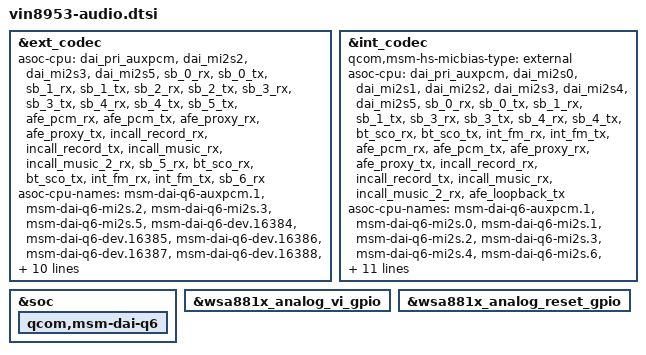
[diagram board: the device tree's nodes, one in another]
&ext_codec {
	/* WARNING: Override
	   Changes:
	   - Remove "proxy_rx", "proxy_tx"
	*/
	asoc-cpu = <&dai_pri_auxpcm>,
		<&dai_mi2s2>, <&dai_mi2s3>, <&dai_mi2s5>,
		<&sb_0_rx>, <&sb_0_tx>, <&sb_1_rx>, <&sb_1_tx>,
		<&sb_2_rx>, <&sb_2_tx>, <&sb_3_rx>, <&sb_3_tx>,
		<&sb_4_rx>, <&sb_4_tx>, <&sb_5_tx>,
		<&afe_pcm_rx>, <&afe_pcm_tx>,
		<&afe_proxy_rx>, <&afe_proxy_tx>,
		<&incall_record_rx>, <&incall_record_tx>,
		<&incall_music_rx>, <&incall_music_2_rx>,
		<&sb_5_rx>, <&bt_sco_rx>, <&bt_sco_tx>,
		<&int_fm_rx>, <&int_fm_tx>, <&sb_6_rx>;

	/* WARNING: Override
	   Changes:
	   - Remove "msm-dai-q6-dev.8194", "msm-dai-q6-dev.8195"
	*/
	asoc-cpu-names = "msm-dai-q6-auxpcm.1",
		"msm-dai-q6-mi2s.2", "msm-dai-q6-mi2s.3",
		"msm-dai-q6-mi2s.5", "msm-dai-q6-dev.16384",
		"msm-dai-q6-dev.16385", "msm-dai-q6-dev.16386",
		"msm-dai-q6-dev.16387", "msm-dai-q6-dev.16388",
		"msm-dai-q6-dev.16389", "msm-dai-q6-dev.16390",
		"msm-dai-q6-dev.16391", "msm-dai-q6-dev.16392",
		"msm-dai-q6-dev.16393", "msm-dai-q6-dev.16395",
		"msm-dai-q6-dev.224", "msm-dai-q6-dev.225",
		"msm-dai-q6-dev.241", "msm-dai-q6-dev.240",
		"msm-dai-q6-dev.32771", "msm-dai-q6-dev.32772",
		"msm-dai-q6-dev.32773", "msm-dai-q6-dev.32770",
		"msm-dai-q6-dev.16394", "msm-dai-q6-dev.12288",
		"msm-dai-q6-dev.12289", "msm-dai-q6-dev.12292",
		"msm-dai-q6-dev.12293", "msm-dai-q6-dev.16396";
};

&int_codec {
	qcom,msm-hs-micbias-type = "external";

	/* WARNING: Override
	   Changes:
	   - Remove "proxy_rx", "proxy_tx"
	*/
	asoc-cpu = <&dai_pri_auxpcm>,
		<&dai_mi2s0>, <&dai_mi2s1>,
		<&dai_mi2s2>, <&dai_mi2s3>,
		<&dai_mi2s4>, <&dai_mi2s5>,
		<&sb_0_rx>, <&sb_0_tx>, <&sb_1_rx>, <&sb_1_tx>,
		<&sb_3_rx>, <&sb_3_tx>, <&sb_4_rx>, <&sb_4_tx>,
		<&bt_sco_rx>, <&bt_sco_tx>,
		<&int_fm_rx>, <&int_fm_tx>,
		<&afe_pcm_rx>, <&afe_pcm_tx>,
		<&afe_proxy_rx>, <&afe_proxy_tx>,
		<&incall_record_rx>, <&incall_record_tx>,
		<&incall_music_rx>, <&incall_music_2_rx>,
		<&afe_loopback_tx>;

	/* WARNING: Override
	   Changes:
	   - Remove "msm-dai-q6-dev.8194", "msm-dai-q6-dev.8195"
	*/
	asoc-cpu-names = "msm-dai-q6-auxpcm.1",
		"msm-dai-q6-mi2s.0", "msm-dai-q6-mi2s.1",
		"msm-dai-q6-mi2s.2", "msm-dai-q6-mi2s.3",
		"msm-dai-q6-mi2s.4", "msm-dai-q6-mi2s.6",
		"msm-dai-q6-dev.16384", "msmdai-q6-dev.16385",
		"msm-dai-q6-dev.16386", "msm-dai-q6-dev.16387",
		"msm-dai-q6-dev.16390", "msm-dai-q6-dev.16391",
		"msm-dai-q6-dev.16392", "msm-dai-q6-dev.16393",
		"msm-dai-q6-dev.12288", "msm-dai-q6-dev.12289",
		"msm-dai-q6-dev.12292", "msm-dai-q6-dev.12293",
		"msm-dai-q6-dev.224", "msm-dai-q6-dev.225",
		"msm-dai-q6-dev.241", "msm-dai-q6-dev.240",
		"msm-dai-q6-dev.32771", "msm-dai-q6-dev.32772",
		"msm-dai-q6-dev.32773", "msm-dai-q6-dev.32770",
		"msm-dai-q6-dev.24577";
};

&soc {
	qcom,msm-dai-q6 {
		/delete-node/ qcom,msm-dai-q6-proxy-rx;
		/delete-node/ qcom,msm-dai-q6-proxy-tx;
	};
};

&wsa881x_analog_vi_gpio {
	/delete-property/ pinctrl-0;
	/delete-property/ pinctrl-1;
};

&wsa881x_analog_reset_gpio {
	/delete-property/ pinctrl-0;
	/delete-property/ pinctrl-1;
};
